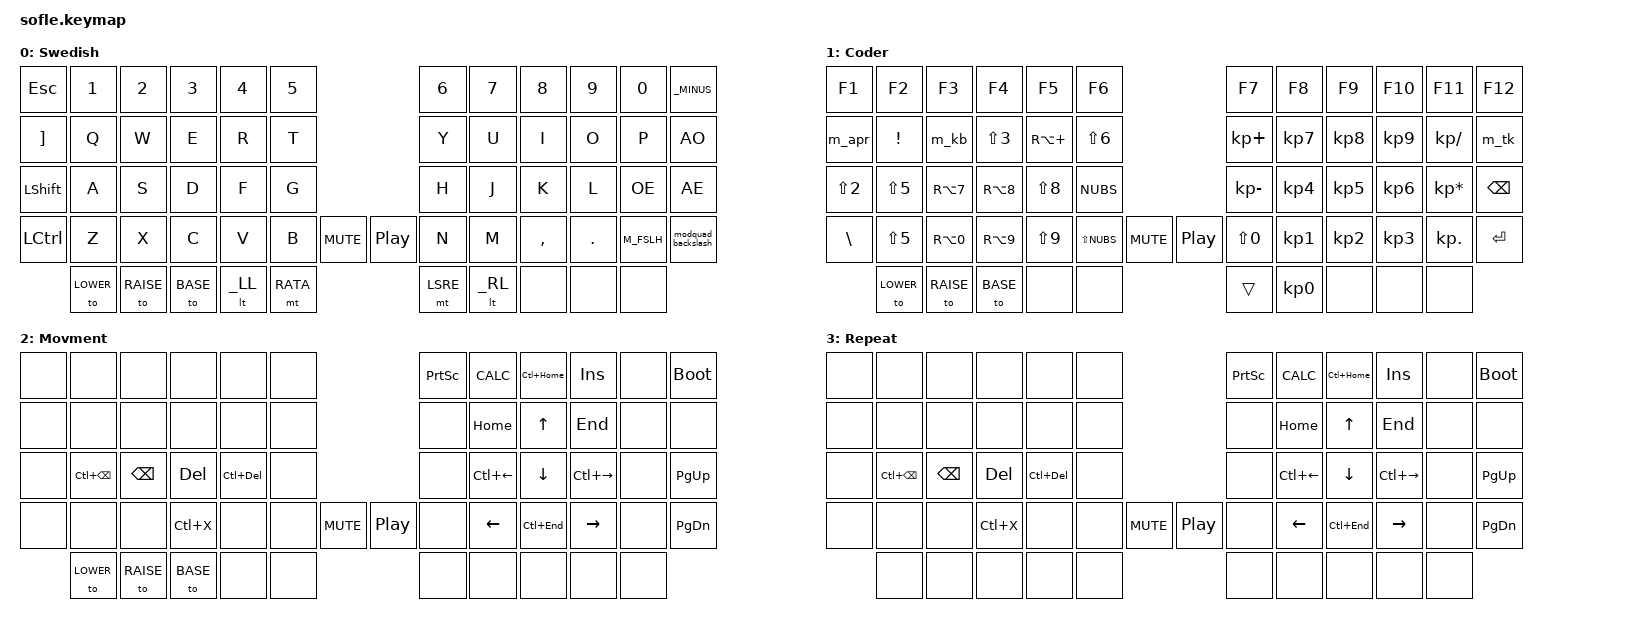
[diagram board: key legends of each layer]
/*
 * Copyright (c) 2020 The ZMK Contributors
 *
 * SPDX-License-Identifier: MIT
 */

#include <behaviors.dtsi>
#include <dt-bindings/zmk/bt.h>
#include <dt-bindings/zmk/ext_power.h>
#include <dt-bindings/zmk/keys.h>
#include <dt-bindings/zmk/rgb.h>

#define _PG GRAVE
#define _PLUS MINUS
#define _ACCENT EQUAL
#define AO LBKT
#define _DCT RIGHT_BRACKET  // for DIAERSIS CIRCUMFLEX TILDE
#define OE SEMICOLON
#define AE APOSTROPHE
#define _APS BACKSLASH
#define _LGP NON_US_BACKSLASH // Less Greater Pipe
#define _MINUS SLASH
#define LSBS LSHIFT BACKSPACE
#define RABS RALT BACKSPACE
#define LABS LALT BACKSPACE
#define LSSP LSHIFT SPACE
#define LSRE LSHIFT RETURN
#define RATA RALT TAB
#define M_FSLH LS(N7)
#define _LL LOWER BACKSPACE
#define _RL RAISE SPACE

#define BASE 0
#define RAISE 2
#define LOWER 1
#define ADJUST 3

/ {
    behaviors {
       modquad_backslash: modquad_backslash {
              compatible = "zmk,behavior-modquad";
              #binding-cells = <0>;
              bindings = <
                     &kp MINUS
                     &kp QMARK
                     &kp PLUS
                     &kp PIPE2
              >;
       };
  };

  macros {
    m_bslh: m_bslh {
       compatible = "zmk,behavior-macro";
       #binding-cells = <0>;
       bindings
            = <&macro_press &kp RALT>
            , <&macro_tap &kp MINUS>
            , <&macro_release &kp RALT>
            ;
    };
    m_tilde: m_tilde {
       compatible = "zmk,behavior-macro";
       #binding-cells = <0>;
       wait-ms = <40>;
       tap-ms = <40>;
       bindings
            = <&macro_press &kp LALT>
            , <&macro_tap &kp KP_N1 &kp KP_N2 &kp KP_N6>
            , <&macro_release &kp LALT>
            ;
    };
    m_apr: m_apr {
       compatible = "zmk,behavior-macro";
       #binding-cells = <0>;
       wait-ms = <40>;
       tap-ms = <40>;
       bindings
            = <&macro_press &kp LALT>
            , <&macro_tap &kp KP_N9 &kp KP_N6>
            , <&macro_release &kp LALT>
            ;
    };
    m_kb: m_kb {
       compatible = "zmk,behavior-macro";
       #binding-cells = <0>;
       wait-ms = <40>;
       tap-ms = <40>;
       bindings
            = <&macro_press &kp LALT>
            , <&macro_tap &kp KP_N6 &kp KP_N4>
            , <&macro_release &kp LALT>
            ;
    };
    m_tk: m_tk {
       compatible = "zmk,behavior-macro";
       #binding-cells = <0>;
       wait-ms = <40>;
       tap-ms = <40>;
       bindings
            = <&macro_press &kp LALT>
            , <&macro_tap &kp KP_N0 &kp KP_N1 &kp KP_N3 &kp KP_N6>
            , <&macro_release &kp LALT>
            ;
    };
  };

    keymap {
       compatible = "zmk,keymap";
       default_layer {
              display-name = "Swedish";    
              bindings = <
// ╭───────────┬───────────┬───────────┬────────────┬────────────┬────────────╮                               ╭───────────┬─────────────┬─────────────┬─────────────┬────────────┬────────────╮
      &kp ESC     &kp N1      &kp N2       &kp N3       &kp N4      &kp N5                                       &kp N6       &kp N7        &kp N8        &kp N9        &kp N0     &kp _MINUS
// ├───────────┼───────────┼───────────┼────────────┼────────────┼────────────┤                               ├───────────┼─────────────┼─────────────┼─────────────┼────────────┼────────────┤
     &kp RBKT     &kp Q       &kp W        &kp E        &kp R       &kp T                                        &kp Y        &kp U         &kp I          &kp O        &kp P        &kp AO
// ├───────────┼───────────┼───────────┼────────────┼────────────┼────────────┤                               ├───────────┼─────────────┼─────────────┼─────────────┼────────────┼────────────┤
     &kp LSHFT    &kp A        &kp S        &kp D       &kp F       &kp G                                        &kp H        &kp J         &kp K          &kp L       &kp OE       &kp AE
// ├───────────┼───────────┼───────────┼────────────┼────────────┼────────────┤ ╔════════════╗ ╔════════════╗ ├───────────┼─────────────┼─────────────┼─────────────┼────────────┼────────────┤
     &kp LCTRL     &kp Z       &kp X        &kp C        &kp V        &kp B       &kp C_MUTE     &kp C_PP         &kp N        &kp M       &kp COMMA      &kp DOT    &kp M_FSLH    &modquad_backslash
// ╰───────────┼───────────┼───────────┼────────────┼────────────┼────────────┤ ╚════════════╝ ╚════════════╝ ├───────────┼─────────────┼─────────────┼─────────────┼────────────┼────────────╯
                 &to LOWER   &to RAISE    &to BASE      &lt _LL     &mt RATA                                     &mt LSRE     &lt _RL         &none         &none        &none
//             ╰───────────┴───────────┴────────────┴────────────┴────────────╯                               ╰───────────┴─────────────┴─────────────┴─────────────┴────────────╯
              >;
              sensor-bindings = <&inc_dec_kp C_VOL_DN C_VOL_UP &inc_dec_kp PG_UP PG_DN>;
       };

       lower_layer {
              display-name = "Coder";    
              bindings = <
// ╭───────────┬───────────┬───────────┬────────────┬────────────┬────────────╮                               ╭───────────┬─────────────┬─────────────┬─────────────┬────────────┬────────────╮
      &kp F1     &kp F2      &kp F3      &kp F4        &kp F5      &kp F6                                       &kp F7       &kp F8        &kp F9        &kp F10       &kp F11      &kp F12  
// ├───────────┼───────────┼───────────┼────────────┼────────────┼────────────┤                               ├───────────┼─────────────┼─────────────┼─────────────┼────────────┼────────────┤
      &m_apr    &kp EXCL      &m_kb      &kp LS(N3)  &kp RA(PLUS)  &kp LS(N6)                                  &kp KP_PLUS    &kp KP_N7     &kp KP_N8    &kp KP_N9   &kp KP_DIVIDE    &m_tk
// ├───────────┼───────────┼───────────┼────────────┼────────────┼────────────┤                               ├───────────┼─────────────┼─────────────┼─────────────┼────────────┼────────────┤
     &kp LS(N2)  &kp LS(N5)  &kp RA(N7)  &kp RA(N8)   &kp LS(N8)   &kp NUBS                                    &kp KP_MINUS   &kp KP_N4     &kp KP_N5    &kp KP_N6  &kp KP_MULTIPLY  &kp BSPC
// ├───────────┼───────────┼───────────┼────────────┼────────────┼────────────┤ ╔════════════╗ ╔════════════╗ ├───────────┼─────────────┼─────────────┼─────────────┼────────────┼────────────┤
     &kp BSLH   &kp LS(N5)  &kp RA(N0)   &kp RA(N9)   &kp LS(N9)  &kp LS(NUBS)    &kp C_MUTE      &kp C_PP     &kp LS(N0)     &kp KP_N1     &kp KP_N2     &kp KP_N3    &kp KP_DOT    &kp ENTER
// ╰───────────┼───────────┼───────────┼────────────┼────────────┼────────────┤ ╚════════════╝ ╚════════════╝ ├───────────┼─────────────┼─────────────┼─────────────┼────────────┼────────────╯
                 &to LOWER   &to RAISE    &to BASE      &none        &none                                       &trans      &kp KP_N0      &none         &none         &none         
//             ╰───────────┴───────────┴────────────┴────────────┴────────────╯                               ╰───────────┴─────────────┴─────────────┴─────────────┴────────────╯
              >;
              sensor-bindings = <&inc_dec_kp C_VOL_DN C_VOL_UP &inc_dec_kp PG_UP PG_DN>;
       };

       raise_layer {
              display-name = "Movment"; 
              bindings = <
// ╭───────────┬───────────┬───────────┬────────────┬────────────┬────────────╮                               ╭───────────┬─────────────┬─────────────┬─────────────┬────────────┬────────────╮
       &none       &none       &none       &none         &none       &none                                      &kp PSCRN   &kp K_CALC   &kp LC(HOME)     &kp INS       &none     &bootloader
// ├───────────┼───────────┼───────────┼────────────┼────────────┼────────────┤                               ├───────────┼─────────────┼─────────────┼─────────────┼────────────┼────────────┤
       &none       &none       &none       &none         &none       &none                                        &none      &kp HOME        &kp UP       &kp END       &none        &none
// ├───────────┼───────────┼───────────┼────────────┼────────────┼────────────┤                               ├───────────┼─────────────┼─────────────┼─────────────┼────────────┼────────────┤
       &none   &kp LC(BSPC)  &kp BSPC     &kp DEL    &kp LC(DEL)     &none                                        &none     &kp LC(LEFT)   &kp DOWN    &kp LC(RIGHT)    &none      &kp PG_UP
// ├───────────┼───────────┼───────────┼────────────┼────────────┼────────────┤ ╔════════════╗ ╔════════════╗ ├───────────┼─────────────┼─────────────┼─────────────┼────────────┼────────────┤
       &none       &none       &none     &kp LC(X)       &none       &none        &kp C_MUTE      &kp C_PP        &none      &kp LEFT     &kp LC(END)    &kp RIGHT      &none      &kp PG_DN
// ╰───────────┼───────────┼───────────┼────────────┼────────────┼────────────┤ ╚════════════╝ ╚════════════╝ ├───────────┼─────────────┼─────────────┼─────────────┼────────────┼────────────╯
                 &to LOWER   &to RAISE    &to BASE     &none         &none                                        &none        &none         &none         &none        &none         
//             ╰───────────┴───────────┴────────────┴────────────┴────────────╯                               ╰───────────┴─────────────┴─────────────┴─────────────┴────────────╯
              >;
              sensor-bindings = <&inc_dec_kp C_VOL_DN C_VOL_UP &inc_dec_kp PG_UP PG_DN>;
       };

       adjust_layer {
              display-name = "Repeat"; 
              bindings = <
// ╭───────────┬───────────┬───────────┬────────────┬────────────┬────────────╮                               ╭───────────┬─────────────┬─────────────┬─────────────┬────────────┬────────────╮
       &none       &none       &none       &none         &none       &none                                      &kp PSCRN   &kp K_CALC   &kp LC(HOME)     &kp INS       &none     &bootloader
// ├───────────┼───────────┼───────────┼────────────┼────────────┼────────────┤                               ├───────────┼─────────────┼─────────────┼─────────────┼────────────┼────────────┤
       &none       &none       &none       &none         &none       &none                                        &none      &kp HOME        &kp UP       &kp END       &none        &none
// ├───────────┼───────────┼───────────┼────────────┼────────────┼────────────┤                               ├───────────┼─────────────┼─────────────┼─────────────┼────────────┼────────────┤
       &none   &kp LC(BSPC)  &kp BSPC     &kp DEL    &kp LC(DEL)     &none                                        &none     &kp LC(LEFT)   &kp DOWN    &kp LC(RIGHT)    &none      &kp PG_UP
// ├───────────┼───────────┼───────────┼────────────┼────────────┼────────────┤ ╔════════════╗ ╔════════════╗ ├───────────┼─────────────┼─────────────┼─────────────┼────────────┼────────────┤
       &none       &none       &none     &kp LC(X)       &none       &none        &kp C_MUTE      &kp C_PP        &none      &kp LEFT     &kp LC(END)    &kp RIGHT      &none      &kp PG_DN
// ╰───────────┼───────────┼───────────┼────────────┼────────────┼────────────┤ ╚════════════╝ ╚════════════╝ ├───────────┼─────────────┼─────────────┼─────────────┼────────────┼────────────╯
                   &none       &none       &none       &none         &none                                        &none        &none         &none         &none        &none         
//             ╰───────────┴───────────┴────────────┴────────────┴────────────╯                               ╰───────────┴─────────────┴─────────────┴─────────────┴────────────╯
              >;
              sensor-bindings = <&inc_dec_kp C_VOL_DN C_VOL_UP &inc_dec_kp PG_UP PG_DN>;
       };
   };
};
